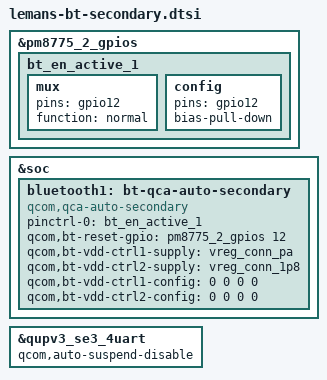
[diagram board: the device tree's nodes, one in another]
#include <dt-bindings/interconnect/qcom,lemans.h>

&pm8775_2_gpios {
	bt_en_active_1: bt_en_active_1 {
		mux {
			pins = "gpio12";
			function = "normal";
		};

		config {
			pins = "gpio12";
			bias-pull-down;
		};
	};
};

&soc {
	bluetooth1: bt-qca-auto-secondary {
		compatible = "qcom,qca-auto-secondary";
		pinctrl-names = "default";
		pinctrl-0 = <&bt_en_active_1>;
		/* BT_EN */
		qcom,bt-reset-gpio = <&pm8775_2_gpios 12 0>;
		qcom,bt-vdd-ctrl1-supply = <&vreg_conn_pa>;
		qcom,bt-vdd-ctrl2-supply = <&vreg_conn_1p8>;

		/* <vol_min, vol_max, load_curr, is_retention_supp> */
		qcom,bt-vdd-ctrl1-config = <0 0 0 0>;
		qcom,bt-vdd-ctrl2-config = <0 0 0 0>;
	};
};

&qupv3_se3_4uart {
	status = "ok";
	qcom,auto-suspend-disable;
};
